VERSION ""

NS_ :

BS_:
BU_: HV_BMS
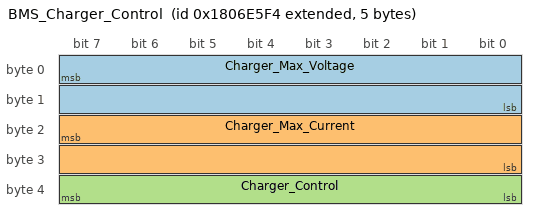
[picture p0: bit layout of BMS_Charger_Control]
BO_ 2550588916 BMS_Charger_Control: 5 HV_BMS
   SG_ Charger_Max_Voltage : 7|16@0- (1,0) [0|0] "" Vector__XXX
   SG_ Charger_Max_Current : 23|16@0- (1,0) [0|0] "" Vector__XXX
   SG_ Charger_Control : 39|8@0+ (1,0) [0|0] "" Vector__XXX

CM_ BU_ HV_BMS "High Voltage Battery Management System";
BA_DEF_ BO_ "GenMsgBackgroundColor" STRING ;
BA_DEF_ BO_ "GenMsgForegroundColor" STRING ;
BA_DEF_DEF_ "GenMsgBackgroundColor" "#1e1e1e";
BA_DEF_DEF_ "GenMsgForegroundColor" "#ffffff";
